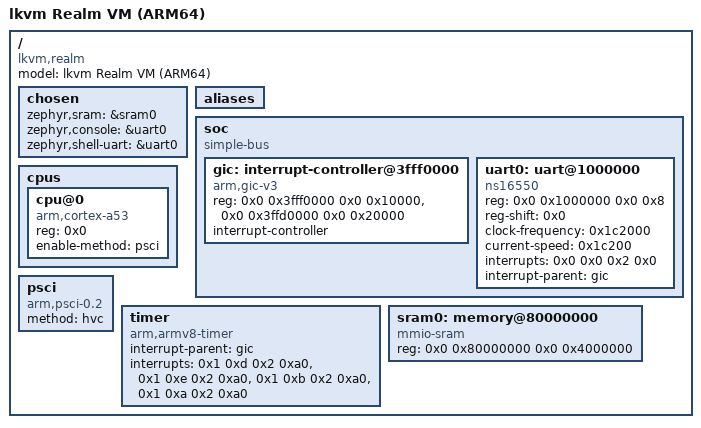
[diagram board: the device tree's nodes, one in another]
/dts-v1/;

/ {
	#address-cells = < 0x2 >;
	#size-cells = < 0x2 >;
	compatible = "lkvm,realm";
	model = "lkvm Realm VM (ARM64)";
	chosen {
		zephyr,sram = &sram0;
		zephyr,console = &uart0;
		zephyr,shell-uart = &uart0;
	};
	aliases {
	};
	soc {
		#address-cells = < 0x2 >;
		#size-cells = < 0x2 >;
		compatible = "simple-bus";
		ranges;
		gic: interrupt-controller@3fff0000 {
			compatible = "arm,gic-v3", "arm,gic";
			reg = < 0x0 0x3fff0000 0x0 0x10000 >, < 0x0 0x3ffd0000 0x0 0x20000 >;
			interrupt-controller;
			#interrupt-cells = < 0x4 >;
			#address-cells = < 0x2 >;
			#size-cells = < 0x2 >;
			status = "okay";
			phandle = < 0x1 >;
		};
		uart0: uart@1000000 {
			compatible = "ns16550";
			reg = < 0x0 0x1000000 0x0 0x8 >;
			reg-shift = < 0x0 >;
			clock-frequency = < 0x1c2000 >;
			current-speed = < 0x1c200 >;
			interrupts = < 0x0 0x0 0x2 0x0 >;
			interrupt-parent = < &gic >;
			status = "okay";
		};
	};
	cpus {
		#address-cells = < 0x1 >;
		#size-cells = < 0x0 >;
		cpu@0 {
			device_type = "cpu";
			compatible = "arm,cortex-a53";
			reg = < 0x0 >;
			enable-method = "psci";
		};
	};
	psci {
		compatible = "arm,psci-0.2";
		method = "hvc";
	};
	timer {
		compatible = "arm,armv8-timer";
		interrupt-parent = < &gic >;
		interrupts = < 0x1 0xd 0x2 0xa0 >, < 0x1 0xe 0x2 0xa0 >, < 0x1 0xb 0x2 0xa0 >, < 0x1 0xa 0x2 0xa0 >;
	};
	sram0: memory@80000000 {
		compatible = "mmio-sram";
		reg = < 0x0 0x80000000 0x0 0x4000000 >;
	};
};
